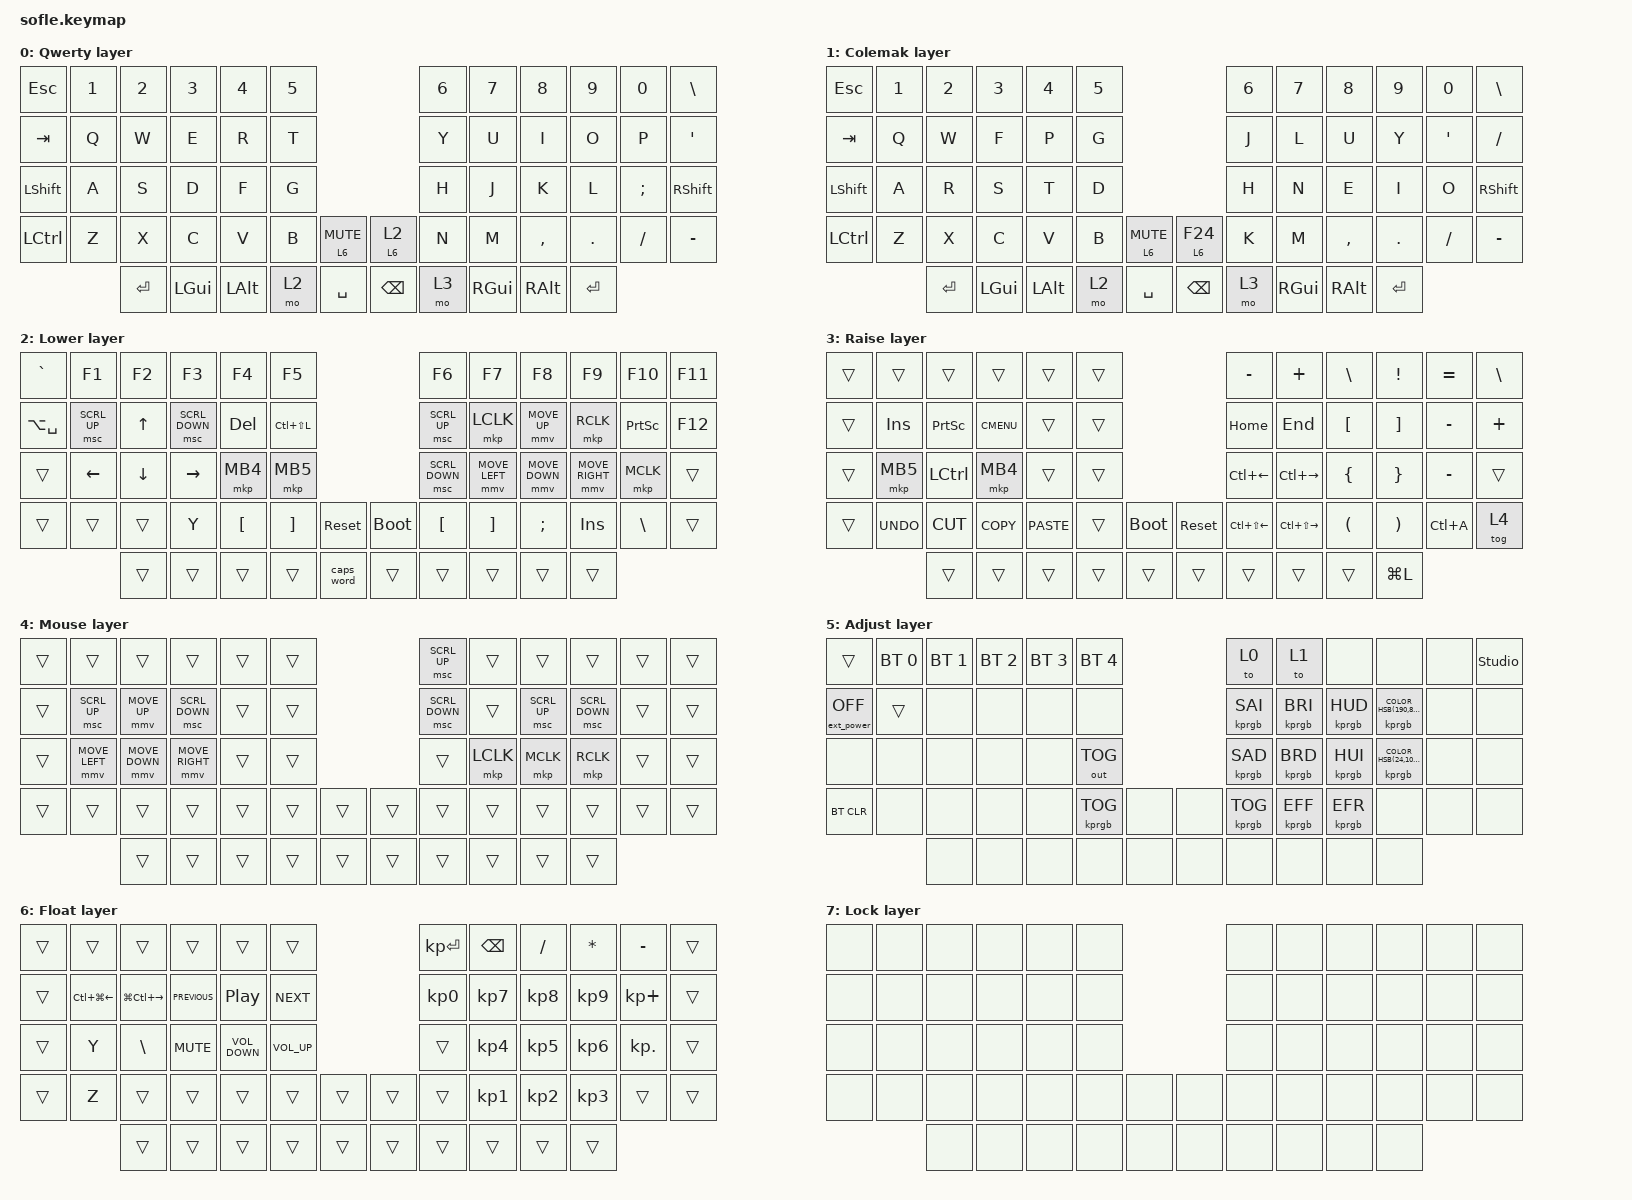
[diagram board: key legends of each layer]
/*
 * Copyright (c) 2020 The ZMK Contributors
 *
 * SPDX-License-Identifier: MIT
 */
/*
 * Temporarily here because nice nano v2 spi is not defined on ZMK Yet
 * Source: https://github.com/zmkfirmware/zmk/blob/main/app/boards/shields/reviung41/boards/nice_nano.overlay
 * GitHub Issue: https://github.com/zmkfirmware/zmk/issues/885
 */

#include <dt-bindings/led/led.h>

#define ZMK_POINTING_DEFAULT_MOVE_VAL 3200  // default: 600
#define ZMK_POINTING_DEFAULT_SCRL_VAL 100    // default: 10

#include <behaviors.dtsi>
#include <dt-bindings/zmk/bt.h>
#include <dt-bindings/zmk/ext_power.h>
#include <dt-bindings/zmk/keys.h>
#include <dt-bindings/zmk/outputs.h>
#include <dt-bindings/zmk/pointing.h>
#include <dt-bindings/zmk/pointing.h>
#include <dt-bindings/zmk/pointing.h>
#include <dt-bindings/zmk/rgb.h>

#define BASE 0
#define COLEMAK 1
#define LOWER 2
#define RAISE 3
#define MOUSE 4
#define ADJUST 5
#define FLOAT 6
#define LOCK 7

&pinctrl {
    spi3_default: spi3_default {
        group1 { psels = <NRF_PSEL(SPIM_MOSI, 0, 8)>; };
    };

    spi3_sleep: spi3_sleep {
        group1 {
            psels = <NRF_PSEL(SPIM_MOSI, 0, 8)>;
            low-power-enable;
        };
    };
};

&spi3 {
    compatible = "nordic,nrf-spim";
    status = "okay";
    pinctrl-0 = <&spi3_default>;
    pinctrl-1 = <&spi3_sleep>;
    pinctrl-names = "default", "sleep";

    led_strip: ws2812@0 {
        compatible = "worldsemi,ws2812-spi";

        /* SPI */

        reg = <0>; /* ignored, but necessary for SPI bindings */
        spi-max-frequency = <4000000>;

        /* WS2812 */

        chain-length = <30>;
        spi-one-frame = <0x70>;
        spi-zero-frame = <0x40>;
        color-mapping = <LED_COLOR_ID_GREEN LED_COLOR_ID_RED LED_COLOR_ID_BLUE>;
    };
};

/*
 * RGB matrix (zmk-rgb-matrix). The per-half LED mappings live in
 * sofle_left.overlay / sofle_right.overlay. Effects, conditions and overlays
 * must be identical (and in the same order) on both halves, so they live here.
 */
/ {
    behaviors {
        kprgb: kprgb {
            compatible = "keypaw,behavior-rgb-matrix";
            #binding-cells = <2>;
            initial-effect = <0>;
            // Single-colour effects start as RGB_COLOR_HSB(190,84,_) (0x29DBFF);
            // with KEYPAW_RGB_MATRIX_SHARED_COLOR the hue/sat/colour keys recolour
            // all of them at once, like the old underglow. Effects marked
            // ignore-user-color keep their own palette. persist-id saves each
            // effect's colour and speed across restarts.
            // Must be explicit: the module's "on unless set" default never applies
            initial-on;
            // Capped at 80% to save battery (the module default is 40)
            max-brightness = <80>;
            initial-brightness = <50>;

            // Typing heatmap: blue -> green -> yellow -> red, spreading to neighbours
            fx_heatmap: fx_heatmap {
                compatible = "keypaw,rgb-matrix-heatmap";
                #binding-cells = <0>;
                persist-id = "fx_heatmap";
                ignore-user-color; // keeps its own colour scheme
                color = <0xFFFFFF>;
                decrease-delay-ms = <25>;
                spread = <300>;
                area-limit = <16>;
                increase-step = <32>;
            };
            fx_solid: fx_solid {
                compatible = "keypaw,rgb-matrix-solid";
                #binding-cells = <0>;
                persist-id = "fx_solid";
                color = <0x29DBFF>;
            };
            fx_breathe: fx_breathe {
                compatible = "keypaw,rgb-matrix-breathe";
                #binding-cells = <0>;
                persist-id = "fx_breathe";
                color = <0x29DBFF>;
                duration = <2400>;
            };
            fx_rainbow: fx_rainbow {
                compatible = "keypaw,rgb-matrix-rainbow";
                #binding-cells = <0>;
                persist-id = "fx_rainbow";
                ignore-user-color; // keeps its own colour scheme
                color = <0xFF0000>;
                duration = <4000>;
                basis = "x";
                direction = "out";
                palette = "rainbow";
            };
            fx_reactive: fx_reactive {
                compatible = "keypaw,rgb-matrix-reactive";
                #binding-cells = <0>;
                persist-id = "fx_reactive";
                color = <0x29DBFF>;
                // Light the pressed key plus a fading circle around it
                spread = "disc";
                spread-radius = <300>;
                background-brightness = <0>;
            };
            // Pressed keys light in a position-based hue (QMK SPLASH)
            fx_gradient: fx_gradient {
                compatible = "keypaw,rgb-matrix-reactive";
                #binding-cells = <0>;
                persist-id = "fx_gradient";
                ignore-user-color; // keeps its own colour scheme
                color = <0xFF0000>;
                palette = "gradient";
                spread = "disc";
                spread-radius = <300>;
                background-brightness = <0>;
            };
            // Pressed keys flash the opposite hue of the colour
            fx_complement: fx_complement {
                compatible = "keypaw,rgb-matrix-reactive";
                #binding-cells = <0>;
                persist-id = "fx_complement";
                color = <0x29DBFF>;
                palette = "complement";
                background-brightness = <0>;
            };
            // Rings expand outward from every pressed key
            fx_ripple: fx_ripple {
                compatible = "keypaw,rgb-matrix-ripple";
                #binding-cells = <0>;
                persist-id = "fx_ripple";
                color = <0x29DBFF>;
                background-brightness = <0>;
            };
        };
    };

    rgb_conditions: rgb_conditions {
        compatible = "keypaw,rgb-conditions";

        cond_lower: cond_lower { compatible = "keypaw,rgb-condition-layer"; layer = <LOWER>; only-topmost; };
        cond_raise: cond_raise { compatible = "keypaw,rgb-condition-layer"; layer = <RAISE>; only-topmost; };
        cond_mouse: cond_mouse { compatible = "keypaw,rgb-condition-layer"; layer = <MOUSE>; only-topmost; };
        cond_adjust: cond_adjust { compatible = "keypaw,rgb-condition-layer"; layer = <ADJUST>; only-topmost; };
        cond_float: cond_float { compatible = "keypaw,rgb-condition-layer"; layer = <FLOAT>; only-topmost; };
        cond_lock: cond_lock { compatible = "keypaw,rgb-condition-layer"; layer = <LOCK>; only-topmost; };

        cond_ble0: cond_ble0 { compatible = "keypaw,rgb-condition-ble"; profile = <0>; };
        cond_ble1: cond_ble1 { compatible = "keypaw,rgb-condition-ble"; profile = <1>; };
        cond_ble2: cond_ble2 { compatible = "keypaw,rgb-condition-ble"; profile = <2>; };
        cond_ble3: cond_ble3 { compatible = "keypaw,rgb-condition-ble"; profile = <3>; };
        cond_ble4: cond_ble4 { compatible = "keypaw,rgb-condition-ble"; profile = <4>; };

        cond_adj_ble0: cond_adj_ble0 { compatible = "keypaw,rgb-condition-and"; conditions = <&cond_adjust &cond_ble0>; };
        cond_adj_ble1: cond_adj_ble1 { compatible = "keypaw,rgb-condition-and"; conditions = <&cond_adjust &cond_ble1>; };
        cond_adj_ble2: cond_adj_ble2 { compatible = "keypaw,rgb-condition-and"; conditions = <&cond_adjust &cond_ble2>; };
        cond_adj_ble3: cond_adj_ble3 { compatible = "keypaw,rgb-condition-and"; conditions = <&cond_adjust &cond_ble3>; };
        cond_adj_ble4: cond_adj_ble4 { compatible = "keypaw,rgb-condition-and"; conditions = <&cond_adjust &cond_ble4>; };

        cond_out_usb: cond_out_usb { compatible = "keypaw,rgb-condition-output"; transport = "usb"; };
        cond_out_ble: cond_out_ble { compatible = "keypaw,rgb-condition-output"; transport = "ble"; };
        cond_adj_usb: cond_adj_usb { compatible = "keypaw,rgb-condition-and"; conditions = <&cond_adjust &cond_out_usb>; };
        cond_adj_bt: cond_adj_bt { compatible = "keypaw,rgb-condition-and"; conditions = <&cond_adjust &cond_out_ble>; };

        // Same threshold as the old STATUS_BATTERY_WARNING_LEVEL
        cond_batt_low: cond_batt_low { compatible = "keypaw,rgb-condition-battery"; below = <15>; };
    };

    rgb_overlays: rgb_overlays {
        compatible = "keypaw,rgb-overlays";

        // Layer indicator on the T key (was LED 1 in the old status overlay)
        ovl_lower: ovl_lower {
            compatible = "keypaw,rgb-overlay"; condition = <&cond_lower>; keys = <17>;
            fx_ovl_lower { compatible = "keypaw,rgb-matrix-solid"; #binding-cells = <0>; color = <0x00C0FF>; };
        };
        ovl_raise: ovl_raise {
            compatible = "keypaw,rgb-overlay"; condition = <&cond_raise>; keys = <17>;
            fx_ovl_raise { compatible = "keypaw,rgb-matrix-solid"; #binding-cells = <0>; color = <0xFF00C0>; };
        };
        ovl_mouse: ovl_mouse {
            compatible = "keypaw,rgb-overlay"; condition = <&cond_mouse>; keys = <17>;
            fx_ovl_mouse { compatible = "keypaw,rgb-matrix-solid"; #binding-cells = <0>; color = <0x00FF40>; };
        };
        ovl_adjust: ovl_adjust {
            compatible = "keypaw,rgb-overlay"; condition = <&cond_adjust>; keys = <17>;
            fx_ovl_adjust { compatible = "keypaw,rgb-matrix-solid"; #binding-cells = <0>; color = <0xFFFF00>; };
        };
        ovl_float: ovl_float {
            compatible = "keypaw,rgb-overlay"; condition = <&cond_float>; keys = <17>;
            fx_ovl_float { compatible = "keypaw,rgb-matrix-solid"; #binding-cells = <0>; color = <0xFF8000>; };
        };
        ovl_lock: ovl_lock {
            compatible = "keypaw,rgb-overlay"; condition = <&cond_lock>; keys = <17>;
            fx_ovl_lock { compatible = "keypaw,rgb-matrix-solid"; #binding-cells = <0>; color = <0xFF0000>; };
        };

        // Adjust layer: active BLE profile lights its BT_SEL key
        ovl_ble0: ovl_ble0 {
            compatible = "keypaw,rgb-overlay"; condition = <&cond_adj_ble0>; keys = <1>;
            fx_ovl_ble0 { compatible = "keypaw,rgb-matrix-solid"; #binding-cells = <0>; color = <0x0060FF>; };
        };
        ovl_ble1: ovl_ble1 {
            compatible = "keypaw,rgb-overlay"; condition = <&cond_adj_ble1>; keys = <2>;
            fx_ovl_ble1 { compatible = "keypaw,rgb-matrix-solid"; #binding-cells = <0>; color = <0x0060FF>; };
        };
        ovl_ble2: ovl_ble2 {
            compatible = "keypaw,rgb-overlay"; condition = <&cond_adj_ble2>; keys = <3>;
            fx_ovl_ble2 { compatible = "keypaw,rgb-matrix-solid"; #binding-cells = <0>; color = <0x0060FF>; };
        };
        ovl_ble3: ovl_ble3 {
            compatible = "keypaw,rgb-overlay"; condition = <&cond_adj_ble3>; keys = <4>;
            fx_ovl_ble3 { compatible = "keypaw,rgb-matrix-solid"; #binding-cells = <0>; color = <0x0060FF>; };
        };
        ovl_ble4: ovl_ble4 {
            compatible = "keypaw,rgb-overlay"; condition = <&cond_adj_ble4>; keys = <5>;
            fx_ovl_ble4 { compatible = "keypaw,rgb-matrix-solid"; #binding-cells = <0>; color = <0x0060FF>; };
        };

        // Adjust layer: selected output on the G key (USB = yellow, BLE = magenta,
        // the old OUTPUT_COLOR_MIN/MAX hues 50 / 300)
        ovl_out_usb: ovl_out_usb {
            compatible = "keypaw,rgb-overlay"; condition = <&cond_adj_usb>; keys = <29>;
            fx_ovl_out_usb { compatible = "keypaw,rgb-matrix-solid"; #binding-cells = <0>; color = <0xFFD500>; };
        };
        ovl_out_bt: ovl_out_bt {
            compatible = "keypaw,rgb-overlay"; condition = <&cond_adj_bt>; keys = <29>;
            fx_ovl_out_bt { compatible = "keypaw,rgb-matrix-solid"; #binding-cells = <0>; color = <0xFF00FF>; };
        };

        // Battery on the key next to B / N, coloured red (0%) -> green (100%)
        // like the old BATTERY_COLOR_MIN/MAX (hue 0 -> 160).
        // Always shown on each half whose own battery is below 15%...
        ovl_batt_low: ovl_batt_low {
            compatible = "keypaw,rgb-overlay-battery";
            condition = <&cond_batt_low>;
            local;
            keys = <42 43>;
            mode = "hue";
            hue-empty = <0>;
            hue-full = <160>;
        };
        // ...and on the Adjust layer for both halves.
        ovl_batt: ovl_batt {
            compatible = "keypaw,rgb-overlay-battery";
            condition = <&cond_adjust>;
            keys = <42 43>;
            mode = "hue";
            hue-empty = <0>;
            hue-full = <160>;
        };
    };
};

&sk {
    release-after-ms = <250>;
    quick-release;
    ignore-modifiers;
};

&lt {
    tapping-term-ms = <125>;
    flavor = "hold-preferred";
};

&mmv {
    x-input-code = <INPUT_REL_X>;
    y-input-code = <INPUT_REL_Y>;
    time-to-max-speed-ms = <1200>;
    acceleration-exponent = <1>;
};

&msc {
    x-input-code = <INPUT_REL_HWHEEL>;
    y-input-code = <INPUT_REL_WHEEL>;
    time-to-max-speed-ms = <1200>;
    acceleration-exponent = <1>;
};

/* END temporary RGB support section */

/ {
    // Activate ADJUST layer by pressing raise and lower

    conditional_layers {
        compatible = "zmk,conditional-layers";

        adjust_layer {
            if-layers = <2 3>;
            then-layer = <5>;
        };
    };

    behaviors {
        layer_hold_toggle: layer_hold_toggle {
            compatible = "zmk,behavior-hold-tap";
            label = "LAYER_HOLD_TOGGLE";
            #binding-cells = <2>;
            flavor = "hold-preferred";
            tapping-term-ms = <125>;
            bindings = <&mo>, <&tog>;
        };

        mouse_tap_layer: mouse_tap_layer {
            compatible = "zmk,behavior-tap-dance";
            label = "MOUSE_TAP_LAYER";
            #binding-cells = <0>;
            bindings = <&mo 2>, <&mo 3>;
        };

        super_backspace: super_backspace {
            compatible = "zmk,behavior-tap-dance";
            label = "SUPER_BACKSPACE";
            #binding-cells = <0>;
            bindings = <&kp BACKSPACE>, <&kp LS(LG(BACKSPACE))>;

            tapping-term-ms = <150>;
        };

        quick_hold_tap: quick_hold_tap {
            compatible = "zmk,behavior-hold-tap";
            label = "QUICK_HOLD_TAP";
            bindings = <&mo>, <&kp>;

            #binding-cells = <2>;
            tapping-term-ms = <125>;
        };

        wacky_tap_dance: wacky_tap_dance {
            compatible = "zmk,behavior-tap-dance";
            label = "WACKY_TAP_DANCE";
            #binding-cells = <0>;
            bindings = <&kp C_MUTE>, <&kp C_PLAY_PAUSE>;

            tapping-term-ms = <125>;
        };

        wacky_layer_hold: wacky_layer_hold {
            compatible = "zmk,behavior-hold-tap";
            label = "WACKY_LAYER_HOLD";
            bindings = <&mo>, <&none>;

            #binding-cells = <2>;
            tapping-term-ms = <125>;
            flavor = "hold-preferred";
        };
    };

    combos {
        compatible = "zmk,combos";

        combo_lock {
            bindings = <&tog 7>;
            key-positions = <53 56 33 26>;
            layers = <0 1 7>;
            timeout-ms = <50>;
        };
    };

    keymap {
        compatible = "zmk,keymap";

        default_layer {
            display-name = "Qwerty layer";
            bindings = <
&kp ESC     &kp N1  &kp N2     &kp N3    &kp N4    &kp N5                                          &kp N6  &kp N7         &kp N8     &kp N9     &kp N0    &kp BACKSLASH
&kp TAB     &kp Q   &kp W      &kp E     &kp R     &kp T                                           &kp Y   &kp U          &kp I      &kp O      &kp P     &kp SQT
&kp LSHIFT  &kp A   &kp S      &kp D     &kp F     &kp G                                           &kp H   &kp J          &kp K      &kp L      &kp SEMI  &kp RIGHT_SHIFT
&kp LCTRL   &kp Z   &kp X      &kp C     &kp V     &kp B   &lt 6 C_MUTE    &layer_hold_toggle 6 2  &kp N   &kp M          &kp COMMA  &kp DOT    &kp FSLH  &kp MINUS
                    &kp ENTER  &kp LGUI  &kp LALT  &mo 2   &kp SPACE       &kp BACKSPACE           &mo 3   &kp RIGHT_GUI  &kp RALT   &kp ENTER
            >;
        };

        colemak_layer {
            display-name = "Colemak layer";
            bindings = <
&kp ESC     &kp N1  &kp N2     &kp N3    &kp N4    &kp N5                                 &kp N6  &kp N7         &kp N8     &kp N9     &kp N0    &kp BACKSLASH
&kp TAB     &kp Q   &kp W      &kp F     &kp P     &kp G                                  &kp J   &kp L          &kp U      &kp Y      &kp SQT   &kp SLASH
&kp LSHIFT  &kp A   &kp R      &kp S     &kp T     &kp D                                  &kp H   &kp N          &kp E      &kp I      &kp O     &kp RIGHT_SHIFT
&kp LCTRL   &kp Z   &kp X      &kp C     &kp V     &kp B   &lt 6 C_MUTE    &lt 6 F24      &kp K   &kp M          &kp COMMA  &kp DOT    &kp FSLH  &kp MINUS
                    &kp ENTER  &kp LGUI  &kp LALT  &mo 2   &kp SPACE       &kp BACKSPACE  &mo 3   &kp RIGHT_GUI  &kp RALT   &kp ENTER
            >;
        };

        lower_layer {
            display-name = "Lower layer";
            bindings = <
&kp GRAVE      &kp F1        &kp F2    &kp F3          &kp F4            &kp F5                                        &kp F6          &kp F7          &kp F8          &kp F9           &kp F10          &kp F11
&kp LA(SPACE)  &msc SCRL_UP  &kp UP    &msc SCRL_DOWN  &kp DELETE        &kp LC(LS(L))                                 &msc SCRL_UP    &mkp LCLK       &mmv MOVE_UP    &mkp RCLK        &kp PRINTSCREEN  &kp F12
&trans         &kp LEFT      &kp DOWN  &kp RIGHT       &mkp MB4          &mkp MB5                                      &msc SCRL_DOWN  &mmv MOVE_LEFT  &mmv MOVE_DOWN  &mmv MOVE_RIGHT  &mkp MCLK        &trans
&trans         &trans        &trans    &kp Y           &kp LEFT_BRACKET  &kp RIGHT_BRACKET  &sys_reset    &bootloader  &kp LBKT        &kp RBKT        &kp SEMI        &kp INSERT       &kp BSLH         &trans
                             &trans    &trans          &trans            &trans             &caps_word    &trans       &trans          &trans          &trans          &trans
            >;
        };

        raise_layer {
            display-name = "Raise layer";
            bindings = <
&trans  &trans      &trans     &trans       &trans       &trans                             &kp MINUS         &kp PLUS           &kp BACKSLASH         &kp EXCL               &kp EQUAL  &kp BACKSLASH
&trans  &kp INS     &kp PSCRN  &kp K_CMENU  &trans       &trans                             &kp HOME          &kp END            &kp LEFT_BRACKET      &kp RIGHT_BRACKET      &kp MINUS  &kp PLUS
&trans  &mkp MB5    &kp LCTRL  &mkp MB4     &trans       &trans                             &kp LC(LEFT)      &kp LC(RIGHT)      &kp LEFT_BRACE        &kp RIGHT_BRACE        &kp MINUS  &trans
&trans  &kp K_UNDO  &kp K_CUT  &kp K_COPY   &kp K_PASTE  &trans  &bootloader    &sys_reset  &kp LC(LS(LEFT))  &kp LC(LS(RIGHT))  &kp LEFT_PARENTHESIS  &kp RIGHT_PARENTHESIS  &kp LC(A)  &tog 4
                    &trans     &trans       &trans       &trans  &trans         &trans      &trans            &trans             &trans                &kp LG(L)
            >;
        };

        Mouse_Layer {
            display-name = "Mouse layer";
            bindings = <
&trans  &trans          &trans          &trans           &trans  &trans                    &msc SCRL_UP    &trans     &trans        &trans          &trans  &trans
&trans  &msc SCRL_UP    &mmv MOVE_UP    &msc SCRL_DOWN   &trans  &trans                    &msc SCRL_DOWN  &trans     &msc SCRL_UP  &msc SCRL_DOWN  &trans  &trans
&trans  &mmv MOVE_LEFT  &mmv MOVE_DOWN  &mmv MOVE_RIGHT  &trans  &trans                    &trans          &mkp LCLK  &mkp MCLK     &mkp RCLK       &trans  &trans
&trans  &trans          &trans          &trans           &trans  &trans  &trans    &trans  &trans          &trans     &trans        &trans          &trans  &trans
                        &trans          &trans           &trans  &trans  &trans    &trans  &trans          &trans     &trans        &trans
            >;
        };

        adjust_layer {
            display-name = "Adjust layer";
            bindings = <
&trans             &bt BT_SEL 0  &bt BT_SEL 1  &bt BT_SEL 2  &bt BT_SEL 3  &bt BT_SEL 4                     &to 0            &to 1            &none            &none                             &none  &studio_unlock
&ext_power EP_OFF  &trans        &none         &none         &none         &none                            &kprgb RGB_SAI  &kprgb RGB_BRI  &kprgb RGB_HUD  &kprgb RGB_COLOR_HSB(190,84,43)  &none  &none
&none              &none         &none         &none         &none         &out OUT_TOG                     &kprgb RGB_SAD  &kprgb RGB_BRD  &kprgb RGB_HUI  &kprgb RGB_COLOR_HSB(24,100,50)  &none  &none
&bt BT_CLR         &none         &none         &none         &none         &kprgb RGB_TOG  &none    &none  &kprgb RGB_TOG  &kprgb RGB_EFF  &kprgb RGB_EFR   &none                            &none  &none
                                 &none         &none         &none         &none            &none    &none  &none            &none            &none            &none
            >;
        };

        float_layer {
            display-name = "Float layer";
            bindings = <
&trans  &trans                  &trans             &trans          &trans             &trans                             &kp KP_ENTER     &kp BACKSPACE    &kp SLASH        &kp ASTERISK     &kp MINUS    &trans
&trans  &kp LC(LG(LEFT_ARROW))  &kp LG(LC(RIGHT))  &kp C_PREVIOUS  &kp C_PLAY_PAUSE   &kp C_NEXT                         &kp KP_NUMBER_0  &kp KP_NUMBER_7  &kp KP_NUMBER_8  &kp KP_NUMBER_9  &kp KP_PLUS  &trans
&trans  &kp Y                   &kp BSLH           &kp C_MUTE      &kp C_VOLUME_DOWN  &kp C_VOLUME_UP                    &trans           &kp KP_NUMBER_4  &kp KP_NUMBER_5  &kp KP_NUMBER_6  &kp KP_DOT   &trans
&trans  &kp Z                   &trans             &trans          &trans             &trans           &trans    &trans  &trans           &kp KP_NUMBER_1  &kp KP_NUMBER_2  &kp KP_NUMBER_3  &trans       &trans
                                &trans             &trans          &trans             &trans           &trans    &trans  &trans           &trans           &trans           &trans
            >;
        };

        lock_layer {
            display-name = "Lock layer";
            bindings = <
&none  &none  &none  &none  &none  &none                  &none  &none  &none  &none  &none  &none
&none  &none  &none  &none  &none  &none                  &none  &none  &none  &none  &none  &none
&none  &none  &none  &none  &none  &none                  &none  &none  &none  &none  &none  &none
&none  &none  &none  &none  &none  &none  &none    &none  &none  &none  &none  &none  &none  &none
              &none  &none  &none  &none  &none    &none  &none  &none  &none  &none
            >;
        };
    };
};
